AUTOSAR XML (schema 00050)
package /IBNvBlkSWC_2
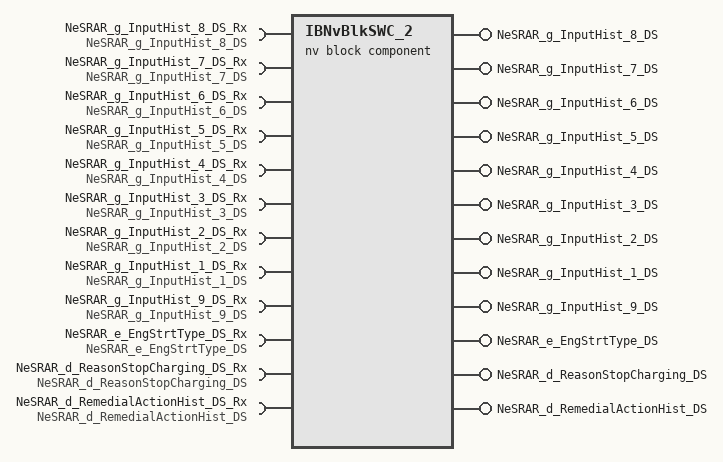
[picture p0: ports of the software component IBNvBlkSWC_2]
  nv block sw component type IBNvBlkSWC_2
    provide port NeSRAR_g_InputHist_8_DS: nv-provide-com-spec{ram-block-init-value=Value:4294967295, rom-block-init-value=Value:4294967295, variable=NeSRAR_g_InputHist_8_DS}, provided-interface=NeSRAR_g_InputHist_8_DS
    require port NeSRAR_g_InputHist_8_DS_Rx: nv-require-com-spec{init-value=Value:4294967295, variable=NeSRAR_g_InputHist_8_DS}, required-interface=NeSRAR_g_InputHist_8_DS
    provide port NeSRAR_g_InputHist_7_DS: nv-provide-com-spec{ram-block-init-value=Value:4294967295, rom-block-init-value=Value:4294967295, variable=NeSRAR_g_InputHist_7_DS}, provided-interface=NeSRAR_g_InputHist_7_DS
    require port NeSRAR_g_InputHist_7_DS_Rx: nv-require-com-spec{init-value=Value:4294967295, variable=NeSRAR_g_InputHist_7_DS}, required-interface=NeSRAR_g_InputHist_7_DS
    provide port NeSRAR_g_InputHist_6_DS: nv-provide-com-spec{ram-block-init-value=Value:4294967295, rom-block-init-value=Value:4294967295, variable=NeSRAR_g_InputHist_6_DS}, provided-interface=NeSRAR_g_InputHist_6_DS
    require port NeSRAR_g_InputHist_6_DS_Rx: nv-require-com-spec{init-value=Value:4294967295, variable=NeSRAR_g_InputHist_6_DS}, required-interface=NeSRAR_g_InputHist_6_DS
    provide port NeSRAR_g_InputHist_5_DS: nv-provide-com-spec{ram-block-init-value=Value:4294967295, rom-block-init-value=Value:4294967295, variable=NeSRAR_g_InputHist_5_DS}, provided-interface=NeSRAR_g_InputHist_5_DS
    require port NeSRAR_g_InputHist_5_DS_Rx: nv-require-com-spec{init-value=Value:4294967295, variable=NeSRAR_g_InputHist_5_DS}, required-interface=NeSRAR_g_InputHist_5_DS
    provide port NeSRAR_g_InputHist_4_DS: nv-provide-com-spec{ram-block-init-value=Value:4294967295, rom-block-init-value=Value:4294967295, variable=NeSRAR_g_InputHist_4_DS}, provided-interface=NeSRAR_g_InputHist_4_DS
    require port NeSRAR_g_InputHist_4_DS_Rx: nv-require-com-spec{init-value=Value:4294967295, variable=NeSRAR_g_InputHist_4_DS}, required-interface=NeSRAR_g_InputHist_4_DS
    provide port NeSRAR_g_InputHist_3_DS: nv-provide-com-spec{ram-block-init-value=Value:4294967295, rom-block-init-value=Value:4294967295, variable=NeSRAR_g_InputHist_3_DS}, provided-interface=NeSRAR_g_InputHist_3_DS
    require port NeSRAR_g_InputHist_3_DS_Rx: nv-require-com-spec{init-value=Value:4294967295, variable=NeSRAR_g_InputHist_3_DS}, required-interface=NeSRAR_g_InputHist_3_DS
    provide port NeSRAR_g_InputHist_2_DS: nv-provide-com-spec{ram-block-init-value=Value:4294967295, rom-block-init-value=Value:4294967295, variable=NeSRAR_g_InputHist_2_DS}, provided-interface=NeSRAR_g_InputHist_2_DS
    require port NeSRAR_g_InputHist_2_DS_Rx: nv-require-com-spec{init-value=Value:4294967295, variable=NeSRAR_g_InputHist_2_DS}, required-interface=NeSRAR_g_InputHist_2_DS
    provide port NeSRAR_g_InputHist_1_DS: nv-provide-com-spec{ram-block-init-value=Value:4294967295, rom-block-init-value=Value:4294967295, variable=NeSRAR_g_InputHist_1_DS}, provided-interface=NeSRAR_g_InputHist_1_DS
    require port NeSRAR_g_InputHist_1_DS_Rx: nv-require-com-spec{init-value=Value:4294967295, variable=NeSRAR_g_InputHist_1_DS}, required-interface=NeSRAR_g_InputHist_1_DS
    provide port NeSRAR_g_InputHist_9_DS: nv-provide-com-spec{ram-block-init-value=Value:0, rom-block-init-value=Value:0, variable=NeSRAR_g_InputHist_9_DS}, provided-interface=NeSRAR_g_InputHist_9_DS
    require port NeSRAR_g_InputHist_9_DS_Rx: nv-require-com-spec{init-value=Value:0, variable=NeSRAR_g_InputHist_9_DS}, required-interface=NeSRAR_g_InputHist_9_DS
    provide port NeSRAR_e_EngStrtType_DS: nv-provide-com-spec{ram-block-init-value=Value:65535, rom-block-init-value=Value:65535, variable=NeSRAR_e_EngStrtType_DS}, provided-interface=NeSRAR_e_EngStrtType_DS
    require port NeSRAR_e_EngStrtType_DS_Rx: nv-require-com-spec{init-value=Value:65535, variable=NeSRAR_e_EngStrtType_DS}, required-interface=NeSRAR_e_EngStrtType_DS
    provide port NeSRAR_d_ReasonStopCharging_DS: nv-provide-com-spec{ram-block-init-value=Value:65535, rom-block-init-value=Value:65535, variable=NeSRAR_d_ReasonStopCharging_DS}, provided-interface=NeSRAR_d_ReasonStopCharging_DS
    require port NeSRAR_d_ReasonStopCharging_DS_Rx: nv-require-com-spec{init-value=Value:65535, variable=NeSRAR_d_ReasonStopCharging_DS}, required-interface=NeSRAR_d_ReasonStopCharging_DS
    provide port NeSRAR_d_RemedialActionHist_DS: nv-provide-com-spec{ram-block-init-value=Value:65535, rom-block-init-value=Value:65535, variable=NeSRAR_d_RemedialActionHist_DS}, provided-interface=NeSRAR_d_RemedialActionHist_DS
    require port NeSRAR_d_RemedialActionHist_DS_Rx: nv-require-com-spec{init-value=Value:65535, variable=NeSRAR_d_RemedialActionHist_DS}, required-interface=NeSRAR_d_RemedialActionHist_DS
    behavior IB_NvBlkSWC_2: data-type-mapping=NVM_DataMappingSet, handle-termination-and-restart=NO-SUPPORT
    nv block descriptor ExpendableNonVolatile_Descr_Core2: support-dirty-flag=true
      nv-block-data-mappings:
        {nv-ram-block-element=autosar-variable-in-impl-datatype={root-variable-data-prototype=ExpendableNonVolatile_RamBlock_Core2, target-data-prototype=ExpendableNonVolatile_Ram_Core2/NeSRAR_g_InputHist_8_DS}, read-nv-data=NeSRAR_g_InputHist_8_DS.NeSRAR_g_InputHist_8_DS}
        {nv-ram-block-element=autosar-variable-in-impl-datatype={root-variable-data-prototype=ExpendableNonVolatile_RamBlock_Core2, target-data-prototype=ExpendableNonVolatile_Ram_Core2/NeSRAR_g_InputHist_8_DS}, written-nv-data=NeSRAR_g_InputHist_8_DS_Rx.NeSRAR_g_InputHist_8_DS}
        {nv-ram-block-element=autosar-variable-in-impl-datatype={root-variable-data-prototype=ExpendableNonVolatile_RamBlock_Core2, target-data-prototype=ExpendableNonVolatile_Ram_Core2/NeSRAR_g_InputHist_7_DS}, read-nv-data=NeSRAR_g_InputHist_7_DS.NeSRAR_g_InputHist_7_DS}
        {nv-ram-block-element=autosar-variable-in-impl-datatype={root-variable-data-prototype=ExpendableNonVolatile_RamBlock_Core2, target-data-prototype=ExpendableNonVolatile_Ram_Core2/NeSRAR_g_InputHist_7_DS}, written-nv-data=NeSRAR_g_InputHist_7_DS_Rx.NeSRAR_g_InputHist_7_DS}
        {nv-ram-block-element=autosar-variable-in-impl-datatype={root-variable-data-prototype=ExpendableNonVolatile_RamBlock_Core2, target-data-prototype=ExpendableNonVolatile_Ram_Core2/NeSRAR_g_InputHist_6_DS}, read-nv-data=NeSRAR_g_InputHist_6_DS.NeSRAR_g_InputHist_6_DS}
        {nv-ram-block-element=autosar-variable-in-impl-datatype={root-variable-data-prototype=ExpendableNonVolatile_RamBlock_Core2, target-data-prototype=ExpendableNonVolatile_Ram_Core2/NeSRAR_g_InputHist_6_DS}, written-nv-data=NeSRAR_g_InputHist_6_DS_Rx.NeSRAR_g_InputHist_6_DS}
        {nv-ram-block-element=autosar-variable-in-impl-datatype={root-variable-data-prototype=ExpendableNonVolatile_RamBlock_Core2, target-data-prototype=ExpendableNonVolatile_Ram_Core2/NeSRAR_g_InputHist_5_DS}, read-nv-data=NeSRAR_g_InputHist_5_DS.NeSRAR_g_InputHist_5_DS}
        {nv-ram-block-element=autosar-variable-in-impl-datatype={root-variable-data-prototype=ExpendableNonVolatile_RamBlock_Core2, target-data-prototype=ExpendableNonVolatile_Ram_Core2/NeSRAR_g_InputHist_5_DS}, written-nv-data=NeSRAR_g_InputHist_5_DS_Rx.NeSRAR_g_InputHist_5_DS}
        {nv-ram-block-element=autosar-variable-in-impl-datatype={root-variable-data-prototype=ExpendableNonVolatile_RamBlock_Core2, target-data-prototype=ExpendableNonVolatile_Ram_Core2/NeSRAR_g_InputHist_4_DS}, read-nv-data=NeSRAR_g_InputHist_4_DS.NeSRAR_g_InputHist_4_DS}
        {nv-ram-block-element=autosar-variable-in-impl-datatype={root-variable-data-prototype=ExpendableNonVolatile_RamBlock_Core2, target-data-prototype=ExpendableNonVolatile_Ram_Core2/NeSRAR_g_InputHist_4_DS}, written-nv-data=NeSRAR_g_InputHist_4_DS_Rx.NeSRAR_g_InputHist_4_DS}
        {nv-ram-block-element=autosar-variable-in-impl-datatype={root-variable-data-prototype=ExpendableNonVolatile_RamBlock_Core2, target-data-prototype=ExpendableNonVolatile_Ram_Core2/NeSRAR_g_InputHist_3_DS}, read-nv-data=NeSRAR_g_InputHist_3_DS.NeSRAR_g_InputHist_3_DS}
        {nv-ram-block-element=autosar-variable-in-impl-datatype={root-variable-data-prototype=ExpendableNonVolatile_RamBlock_Core2, target-data-prototype=ExpendableNonVolatile_Ram_Core2/NeSRAR_g_InputHist_3_DS}, written-nv-data=NeSRAR_g_InputHist_3_DS_Rx.NeSRAR_g_InputHist_3_DS}
        {nv-ram-block-element=autosar-variable-in-impl-datatype={root-variable-data-prototype=ExpendableNonVolatile_RamBlock_Core2, target-data-prototype=ExpendableNonVolatile_Ram_Core2/NeSRAR_g_InputHist_2_DS}, read-nv-data=NeSRAR_g_InputHist_2_DS.NeSRAR_g_InputHist_2_DS}
        {nv-ram-block-element=autosar-variable-in-impl-datatype={root-variable-data-prototype=ExpendableNonVolatile_RamBlock_Core2, target-data-prototype=ExpendableNonVolatile_Ram_Core2/NeSRAR_g_InputHist_2_DS}, written-nv-data=NeSRAR_g_InputHist_2_DS_Rx.NeSRAR_g_InputHist_2_DS}
        {nv-ram-block-element=autosar-variable-in-impl-datatype={root-variable-data-prototype=ExpendableNonVolatile_RamBlock_Core2, target-data-prototype=ExpendableNonVolatile_Ram_Core2/NeSRAR_g_InputHist_1_DS}, read-nv-data=NeSRAR_g_InputHist_1_DS.NeSRAR_g_InputHist_1_DS}
        {nv-ram-block-element=autosar-variable-in-impl-datatype={root-variable-data-prototype=ExpendableNonVolatile_RamBlock_Core2, target-data-prototype=ExpendableNonVolatile_Ram_Core2/NeSRAR_g_InputHist_1_DS}, written-nv-data=NeSRAR_g_InputHist_1_DS_Rx.NeSRAR_g_InputHist_1_DS}
        {nv-ram-block-element=autosar-variable-in-impl-datatype={root-variable-data-prototype=ExpendableNonVolatile_RamBlock_Core2, target-data-prototype=ExpendableNonVolatile_Ram_Core2/NeSRAR_g_InputHist_9_DS}, read-nv-data=NeSRAR_g_InputHist_9_DS.NeSRAR_g_InputHist_9_DS}
        {nv-ram-block-element=autosar-variable-in-impl-datatype={root-variable-data-prototype=ExpendableNonVolatile_RamBlock_Core2, target-data-prototype=ExpendableNonVolatile_Ram_Core2/NeSRAR_g_InputHist_9_DS}, written-nv-data=NeSRAR_g_InputHist_9_DS_Rx.NeSRAR_g_InputHist_9_DS}
        {nv-ram-block-element=autosar-variable-in-impl-datatype={root-variable-data-prototype=ExpendableNonVolatile_RamBlock_Core2, target-data-prototype=ExpendableNonVolatile_Ram_Core2/NeSRAR_e_EngStrtType_DS}, read-nv-data=NeSRAR_e_EngStrtType_DS.NeSRAR_e_EngStrtType_DS}
        {nv-ram-block-element=autosar-variable-in-impl-datatype={root-variable-data-prototype=ExpendableNonVolatile_RamBlock_Core2, target-data-prototype=ExpendableNonVolatile_Ram_Core2/NeSRAR_e_EngStrtType_DS}, written-nv-data=NeSRAR_e_EngStrtType_DS_Rx.NeSRAR_e_EngStrtType_DS}
        {nv-ram-block-element=autosar-variable-in-impl-datatype={root-variable-data-prototype=ExpendableNonVolatile_RamBlock_Core2, target-data-prototype=ExpendableNonVolatile_Ram_Core2/NeSRAR_d_ReasonStopCharging_DS}, read-nv-data=NeSRAR_d_ReasonStopCharging_DS.NeSRAR_d_ReasonStopCharging_DS}
        {nv-ram-block-element=autosar-variable-in-impl-datatype={root-variable-data-prototype=ExpendableNonVolatile_RamBlock_Core2, target-data-prototype=ExpendableNonVolatile_Ram_Core2/NeSRAR_d_ReasonStopCharging_DS}, written-nv-data=NeSRAR_d_ReasonStopCharging_DS_Rx.NeSRAR_d_ReasonStopCharging_DS}
        {nv-ram-block-element=autosar-variable-in-impl-datatype={root-variable-data-prototype=ExpendableNonVolatile_RamBlock_Core2, target-data-prototype=ExpendableNonVolatile_Ram_Core2/NeSRAR_d_RemedialActionHist_DS}, read-nv-data=NeSRAR_d_RemedialActionHist_DS.NeSRAR_d_RemedialActionHist_DS}
        {nv-ram-block-element=autosar-variable-in-impl-datatype={root-variable-data-prototype=ExpendableNonVolatile_RamBlock_Core2, target-data-prototype=ExpendableNonVolatile_Ram_Core2/NeSRAR_d_RemedialActionHist_DS}, written-nv-data=NeSRAR_d_RemedialActionHist_DS_Rx.NeSRAR_d_RemedialActionHist_DS}
      nv block needs NvBlockNeeds: calc-ram-block-crc=false, check-static-block-id=false, readonly=false, resistant-to-changed-sw=false, restore-at-start=true, store-at-shutdown=true, store-cyclic=false, store-emergency=false, store-immediate=false, use-auto-validation-at-shut-down=false, use-crc-comp-mechanism=true, write-only-once=false, write-verification=false
      ram block ExpendableNonVolatile_RamBlock_Core2: type=ExpendableNonVolatile_Ram_Core2, init-value={short-label=ExpendableNonVolatile_Ram_Core2, fields=[NeSRAR_g_InputHist_8_DS:4294967295, NeSRAR_g_InputHist_7_DS:4294967295, NeSRAR_g_InputHist_6_DS:4294967295, NeSRAR_g_InputHist_5_DS:4294967295, NeSRAR_g_InputHist_4_DS:4294967295, NeSRAR_g_InputHist_3_DS:4294967295, NeSRAR_g_InputHist_2_DS:4294967295, NeSRAR_g_InputHist_1_DS:4294967295, NeSRAR_g_InputHist_9_DS:0, NeSRAR_e_EngStrtType_DS:65535, NeSRAR_d_ReasonStopCharging_DS:65535, NeSRAR_d_RemedialActionHist_DS:65535, Reserved1:0, Reserved2:0, Reserved3:0, Reserved4:0, Reserved5:0, Reserved6:0, Reserved7:0, Reserved8:0, Reserved9:0, Reserved10:0, Reserved11:0, Reserved12:0, Reserved13:0, Reserved14:0, Reserved15:0, Reserved16:0, Reserved17:0, Reserved18:0, Reserved19:0, Reserved20:0, Reserved21:0, Reserved22:0, Reserved23:0, Reserved24:0, Reserved25:0, Reserved26:0]}
      rom block ExpendableNonVolatile_RomBlock_Core2: type=ExpendableNonVolatile_Rom_Core2, init-value={short-label=ExpendableNonVolatile_Rom_Core2, fields=[NeSRAR_g_InputHist_8_DS:4294967295, NeSRAR_g_InputHist_7_DS:4294967295, NeSRAR_g_InputHist_6_DS:4294967295, NeSRAR_g_InputHist_5_DS:4294967295, NeSRAR_g_InputHist_4_DS:4294967295, NeSRAR_g_InputHist_3_DS:4294967295, NeSRAR_g_InputHist_2_DS:4294967295, NeSRAR_g_InputHist_1_DS:4294967295, NeSRAR_g_InputHist_9_DS:0, NeSRAR_e_EngStrtType_DS:65535, NeSRAR_d_ReasonStopCharging_DS:65535, NeSRAR_d_RemedialActionHist_DS:65535, Reserved1:0, Reserved2:0, Reserved3:0, Reserved4:0, Reserved5:0, Reserved6:0, Reserved7:0, Reserved8:0, Reserved9:0, Reserved10:0, Reserved11:0, Reserved12:0, Reserved13:0, Reserved14:0, Reserved15:0, Reserved16:0, Reserved17:0, Reserved18:0, Reserved19:0, Reserved20:0, Reserved21:0, Reserved22:0, Reserved23:0, Reserved24:0, Reserved25:0, Reserved26:0]}
package /IFEepNVBlk_2
  impl type ExpendableNonVolatile_Ram_Core2: category=STRUCTURE
    38 x element, all with category=TYPE_REFERENCE:
      NeSRAR_g_InputHist_8_DS: implementation-data-type=uint32
      NeSRAR_g_InputHist_7_DS: implementation-data-type=uint32
      NeSRAR_g_InputHist_6_DS: implementation-data-type=uint32
      NeSRAR_g_InputHist_5_DS: implementation-data-type=uint32
      NeSRAR_g_InputHist_4_DS: implementation-data-type=uint32
      NeSRAR_g_InputHist_3_DS: implementation-data-type=uint32
      NeSRAR_g_InputHist_2_DS: implementation-data-type=uint32
      NeSRAR_g_InputHist_1_DS: implementation-data-type=uint32
      NeSRAR_g_InputHist_9_DS: implementation-data-type=uint32
      NeSRAR_e_EngStrtType_DS: implementation-data-type=uint16
      NeSRAR_d_ReasonStopCharging_DS: implementation-data-type=uint16
      NeSRAR_d_RemedialActionHist_DS: implementation-data-type=uint16
      Reserved{1..26}: implementation-data-type=uint8
  impl type ExpendableNonVolatile_Rom_Core2: category=STRUCTURE
    38 x element, all with category=TYPE_REFERENCE:
      NeSRAR_g_InputHist_8_DS: implementation-data-type=uint32
      NeSRAR_g_InputHist_7_DS: implementation-data-type=uint32
      NeSRAR_g_InputHist_6_DS: implementation-data-type=uint32
      NeSRAR_g_InputHist_5_DS: implementation-data-type=uint32
      NeSRAR_g_InputHist_4_DS: implementation-data-type=uint32
      NeSRAR_g_InputHist_3_DS: implementation-data-type=uint32
      NeSRAR_g_InputHist_2_DS: implementation-data-type=uint32
      NeSRAR_g_InputHist_1_DS: implementation-data-type=uint32
      NeSRAR_g_InputHist_9_DS: implementation-data-type=uint32
      NeSRAR_e_EngStrtType_DS: implementation-data-type=uint16
      NeSRAR_d_ReasonStopCharging_DS: implementation-data-type=uint16
      NeSRAR_d_RemedialActionHist_DS: implementation-data-type=uint16
      Reserved{1..26}: implementation-data-type=uint8
